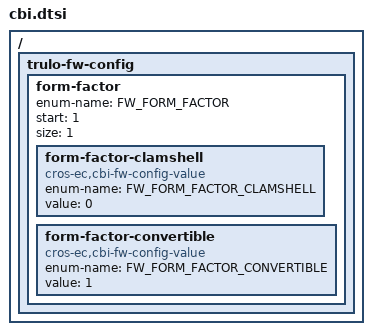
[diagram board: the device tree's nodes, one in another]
/* Copyright 2024 The ChromiumOS Authors
 * Use of this source code is governed by a BSD-style license that can be
 * found in the LICENSE file.
 */

/ {
/* Uldrenite-specific fw_config fields. */
	trulo-fw-config {
		/*
		 * FW_CONFIG field to defined for THERMAL SOLUTION.
		 */
		form-factor {
			enum-name = "FW_FORM_FACTOR";
			start = <1>;
			size = <1>;

			form-factor-clamshell {
				compatible = "cros-ec,cbi-fw-config-value";
				enum-name = "FW_FORM_FACTOR_CLAMSHELL";
				value = <0>;
			};
			form-factor-convertible {
				compatible = "cros-ec,cbi-fw-config-value";
				enum-name = "FW_FORM_FACTOR_CONVERTIBLE";
				value = <1>;
			};
		};
	};
};
